# ipro7 register map
Vendor: intelpro; Series: BTBLE
CPU: ipro7, little endian
Registers are 32-bit, read-write, reset 0x0 unless marked. A register's access mark holds for its fields unless they carry their own. Offsets are from the block's base; [hi:lo] are bit positions.

## KYS
Base 0x30016000
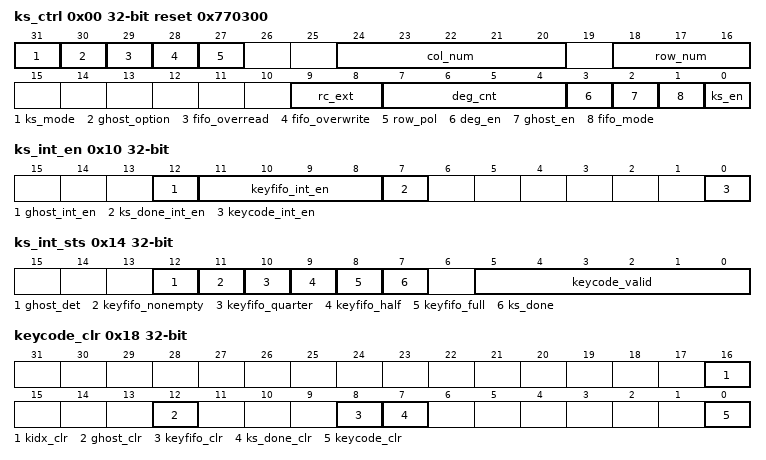
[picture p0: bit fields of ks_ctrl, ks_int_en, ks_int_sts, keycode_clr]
0x00 ks_ctrl reset 0x770300
  [31] ks_mode
  [30] ghost_option
  [29] fifo_overread
  [28] fifo_overwrite
  [27] row_pol
  [24:20] col_num — col_num + 1 (col max=20)
  [18:16] row_num — row_num + 1 (row max=8)
  [9:8] rc_ext — idle duration between column scans
  [7:4] deg_cnt
  [3] deg_en — deglitch
  [2] ghost_en — ghost key event detection enable
  [1] fifo_mode — fifo mode for keycode (incremental)
  [0] ks_en
0x10 ks_int_en
  [12] ghost_int_en
  [11:8] keyfifo_int_en — [11] FIFO>=1 [10] FIFO>=2 [9] FIFO>=4 [8] FIFO Full
  [7] ks_done_int_en
  [0] keycode_int_en
0x14 ks_int_sts (reset mask 0xFFFFE040)
  [12] ghost_det ro — ghost key event detection status (keycode MSB=1 is ghost key)
  [11] keyfifo_nonempty ro — keycode FIFO nonempty detection
  [10] keyfifo_quarter ro — keycode FIFO quarter detection
  [9] keyfifo_half ro — keycode FIFO half detection
  [8] keyfifo_full ro — keycode FIFO full detection
  [7] ks_done ro — keycode scan done
  [5:0] keycode_valid ro
0x18 keycode_clr
  [16] kidx_clr
  [12] ghost_clr — ghost key event detection clear
  [8] keyfifo_clr — keycode FIFO full clear
  [7] ks_done_clr
  [0] keycode_clr
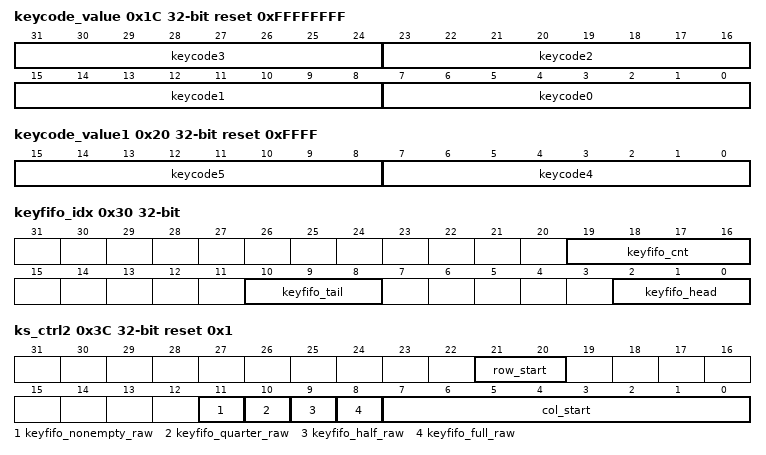
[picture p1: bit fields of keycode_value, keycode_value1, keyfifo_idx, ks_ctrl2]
0x1C keycode_value reset 0xFFFFFFFF (reset mask 0x0)
  [31:24] keycode3 ro
  [23:16] keycode2 ro
  [15:8] keycode1 ro
  [7:0] keycode0 ro — Col = keycode / (row_num+1) Row = keycode % (row_num+1)
0x20 keycode_value1 reset 0xFFFF (reset mask 0xFFFF0000)
  [15:8] keycode5 ro, [7:0] keycode4 ro
0x30 keyfifo_idx (reset mask 0xFFF0F8F8)
  [19:16] keyfifo_cnt ro — keycode FIFO valid number
  [10:8] keyfifo_tail ro — keycode FIFO tail (0~7)
  [2:0] keyfifo_head ro — keycode FIFO head (0~7)
0x34 keyfifo_value reset 0xFF (reset mask 0xFFFFFF00)
  [7:0] keyfifo_value ro — keycode FIFO value (each read head+1 until tail)
0x3C ks_ctrl2 reset 0x1 (reset mask 0xFFFFF0FF)
  [21:20] row_start — optional to skip row 0~3
  [11] keyfifo_nonempty_raw ro
  [10] keyfifo_quarter_raw ro
  [9] keyfifo_half_raw ro
  [8] keyfifo_full_raw ro
  [7:0] col_start — optional to skip col 0~7 (one-hot)

## SCALER_HYDRE
Base 0x30045000
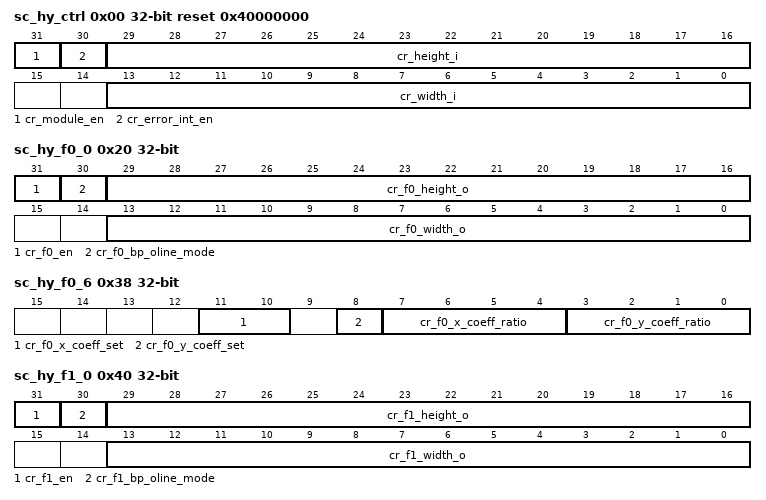
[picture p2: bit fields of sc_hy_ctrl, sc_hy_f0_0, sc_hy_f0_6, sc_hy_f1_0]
0x00 sc_hy_ctrl reset 0x40000000
  [31] cr_module_en — Module enable
  [30] cr_error_int_en — Error interrupt enable
  [29:16] cr_height_i — Input image height
  [13:0] cr_width_i — Input image width
0x20 sc_hy_f0_0
  [31] cr_f0_en — Output frame enable 1'b0 - Bypass input image
  [30] cr_f0_bp_oline_mode — While cr_fx_width_o > cr_width_i && cr_fx_width_o>2304, set this bit to 1
  [29:16] cr_f0_height_o — Output frame height
  [13:0] cr_f0_width_o — Output frame width
0x24 sc_hy_f0_1
  [11:0] cr_f0_wblank_o — H-blanking value in v-blanking
0x28 sc_hy_f0_2
  [27:0] cr_f0_y_ini — Output frame vetical direction initial value
0x2C sc_hy_f0_3
  [27:0] cr_f0_x_ini — Output frame horizational direction initial value
0x30 sc_hy_f0_4
  [21:0] cr_f0_y_step — Output frame vetical direction step
0x34 sc_hy_f0_5
  [21:0] cr_f0_x_step — Output frame horizational direction step
0x38 sc_hy_f0_6
  [11:10] cr_f0_x_coeff_set — Output frame horizational coefficient selection
  [8] cr_f0_y_coeff_set — Output frame vetical coefficient selection
  [7:4] cr_f0_x_coeff_ratio — Output frame horizational coefficient ratio
  [3:0] cr_f0_y_coeff_ratio — Output frame vetical coefficient ratio
0x3C sc_hy_f0_7 reset 0x10
  [11:0] cr_f0_bp_oline_act_cnt — Effect only when cr_fx_bp_oline_mode==1 Suggest to set to cr_fx_width_o/2
0x40 sc_hy_f1_0
  [31] cr_f1_en — Output frame enable 1'b0 - Bypass input image
  [30] cr_f1_bp_oline_mode — While cr_fx_width_o > cr_width_i && cr_fx_width_o>2304, set this bit to 1
  [29:16] cr_f1_height_o — Output frame height
  [13:0] cr_f1_width_o — Output frame width
0x44 sc_hy_f1_1
  [11:0] cr_f1_wblank_o — H-blanking value in v-blanking
0x48 sc_hy_f1_2
  [27:0] cr_f1_y_ini — Output frame vetical direction initial value
0x4C sc_hy_f1_3
  [27:0] cr_f1_x_ini — Output frame horizational direction initial value
0x50 sc_hy_f1_4
  [21:0] cr_f1_y_step — Output frame vetical direction step
0x54 sc_hy_f1_5
  [21:0] cr_f1_x_step — Output frame horizational direction step
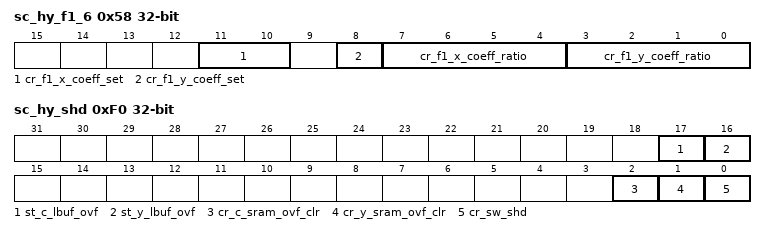
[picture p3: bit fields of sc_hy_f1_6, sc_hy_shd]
0x58 sc_hy_f1_6
  [11:10] cr_f1_x_coeff_set — Output frame horizational coefficient selection
  [8] cr_f1_y_coeff_set — Output frame vetical coefficient selection
  [7:4] cr_f1_x_coeff_ratio — Output frame horizational coefficient ratio
  [3:0] cr_f1_y_coeff_ratio — Output frame vetical coefficient ratio
0x5C sc_hy_f1_7 reset 0x10
  [11:0] cr_f1_bp_oline_act_cnt — Effect only when cr_fx_bp_oline_mode==1 Suggest to set to cr_fx_width_o/2
0xF0 sc_hy_shd (reset mask 0xFFFCFFFF)
  [17] st_c_lbuf_ovf ro — C line-buffer over flow status
  [16] st_y_lbuf_ovf ro — Y line-buffer over flow status
  [2] cr_c_sram_ovf_clr wo — C line-buffer over flow status clear
  [1] cr_y_sram_ovf_clr wo — Y line-buffer over flow status clear
  [0] cr_sw_shd wo — Force software shadow
